# ATSAMRH71F20B device description
Architecture: CORTEX-M7; Family: SAMRH; Series: SAMRH71
Registers are 32-bit, read-write, no defined reset value unless marked. A register's access mark holds for its fields unless they carry their own. Offsets are from the block's base; [hi:lo] are bit positions; {n}, {i} and the like mark numbered series; 'fields as' and 'values as' point back to an identical list.

## HEMC
Instances: HEMC 0x40080000
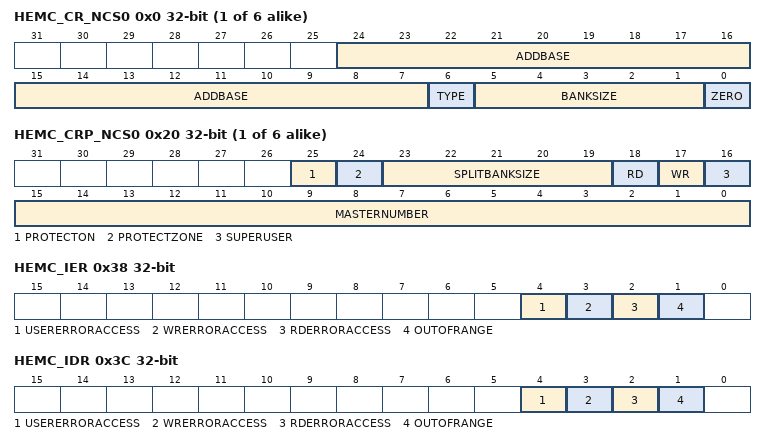
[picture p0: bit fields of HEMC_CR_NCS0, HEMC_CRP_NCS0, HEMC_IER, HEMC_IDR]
{0x0+4i} HEMC_CR_NCS{i} (i=0..5) — HEMC Control Register NCS {i}
  [24:7] ADDBASE — relative base address of NCS area
  [6] TYPE — type of memory used
  [5:1] BANKSIZE
    0=_8KB (8Kbytes); 1=_16KB (16Kbytes); 2=_32KB (32Kbytes); 3=_64KB (64Kbytes); 4=_128KB (128Kbytes); 5=_256KB (256Kbytes); 6=_512KB (512Kbytes); 7=_1MB (1Mbytes); 8=_2MB (2Mbytes); 9=_4MB (4Mbytes); 10=_8MB (8Mbytes); 11=_16MB (16Mbytes); 12=_32MB (32Mbytes); 13=_64MB (64Mbytes); 14=_128MB (128Mbytes); 15=_256MB (256Mbytes (Default)); 16=_512MB (512Mbytes); 31=NOT_USED
  [0] ZERO — fixed to 0
0x18 HEMC_CTRL — HEMC Polarity Control register
  [0] POL — External control buffer active polarity
{0x20+4i} HEMC_CRP_NCS{i} (i=0..5) — HEMC Control Register Protection NCS {i}
  [25] PROTECTON — protection activation
  [24] PROTECTZONE — select area protected
  [23:19] SPLITBANKSIZE — bank size internal separation
  [18] RD — Read Access
  [17] WR — Write Access
  [16] SUPERUSER — User or Superuser access
  [15:0] MASTERNUMBER — Master Number ID
0x38 HEMC_IER wo — HEMC Interrupt Enable Register
  [4] USERERRORACCESS — user or superuser access error
  [3] WRERRORACCESS — write access error
  [2] RDERRORACCESS — read access error
  [1] OUTOFRANGE
0x3C HEMC_IDR wo — HEMC Interrupt Disable Register
  fields as HEMC_IER
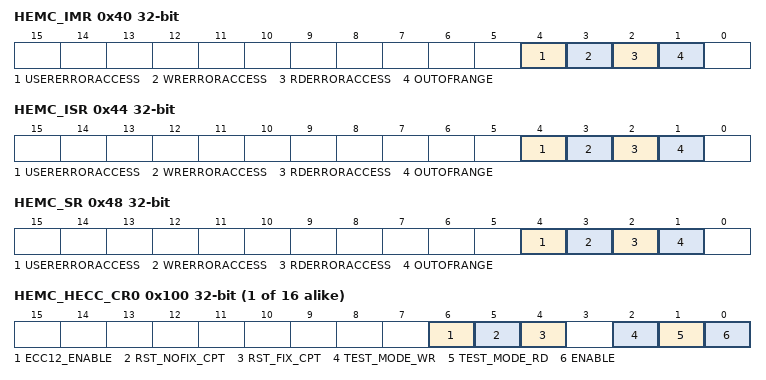
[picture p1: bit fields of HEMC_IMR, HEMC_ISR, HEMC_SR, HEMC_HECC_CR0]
0x40 HEMC_IMR ro — HEMC Interrupt Mask Register
  fields as HEMC_IER
0x44 HEMC_ISR ro — HEMC Interrupt Status Register
  [4] USERERRORACCESS — User or SuperUser Error Access
  [3] WRERRORACCESS — Write access error
  [2] RDERRORACCESS — read access error
  [1] OUTOFRANGE
0x48 HEMC_SR ro — HEMC Status Register
  [4] USERERRORACCESS — User or SuperUser Error Access
  [3] WRERRORACCESS — Write access error
  [2] RDERRORACCESS — Read access error
  [1] OUTOFRANGE
{0x100+4i} HEMC_HECC_CR{i} (i=0..15) — HECC Control Register (ChannelNumbers = 0) {i}
  [6] ECC12_ENABLE — BCH ECC enable
  [5] RST_NOFIX_CPT — reset the un-fixable error counter
  [4] RST_FIX_CPT — reset the fixable error counter
  [2] TEST_MODE_WR — test mode of ECC protection - write mode
  [1] TEST_MODE_RD — test mode of ECC protection - read mode
  [0] ENABLE — ECC protection enable
{0x140+4i} HEMC_HECC_TESTCB{i} (i=0..15) — HECC Test mode Register (ChannelNumbers = 0) {i}
  [15:0] TCB1 — test check bit (16 bit)
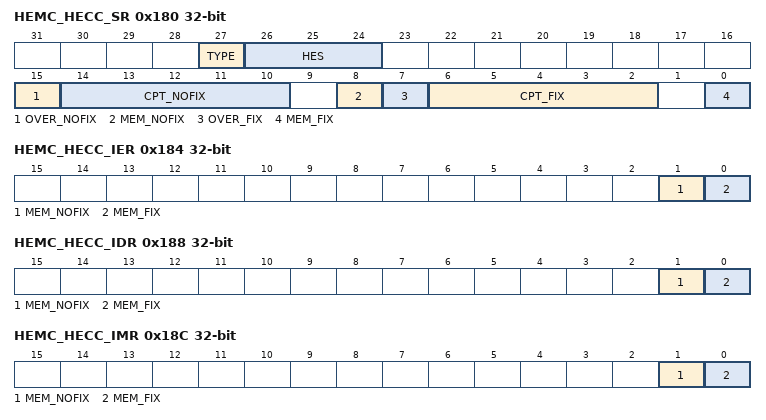
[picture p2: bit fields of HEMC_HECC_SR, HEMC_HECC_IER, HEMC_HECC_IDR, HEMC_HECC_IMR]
0x180 HEMC_HECC_SR ro — HECC Status Register
  [27] TYPE — write or read access
  [26:24] HES — Hardware Error Size
  [15] OVER_NOFIX — counter overflow
  [14:10] CPT_NOFIX — 5 bits counter
  [8] MEM_NOFIX — Un-fixable error status
  [7] OVER_FIX — counter overflow
  [6:2] CPT_FIX — 5 bits counter
  [0] MEM_FIX — Fixable error status
0x184 HEMC_HECC_IER wo — HECC Interrupt Enable Register
  [1] MEM_NOFIX — Un-fixable error
  [0] MEM_FIX — Fixable error
0x188 HEMC_HECC_IDR wo — HECC Interrupt Disable Register
  [1] MEM_NOFIX — un-fixable error
  [0] MEM_FIX — fixable error
0x18C HEMC_HECC_IMR ro — HECC Interrupt Mask Register
  [1] MEM_NOFIX — un-fixable error
  [0] MEM_FIX — fixable error
0x190 HEMC_HECC_FAILAR ro — HECC Fail address register
  [31:0] ADDRESS — address of the error detected

## HSMC — Harden Static Memory Controller
Instances: HSMC 0x40081000
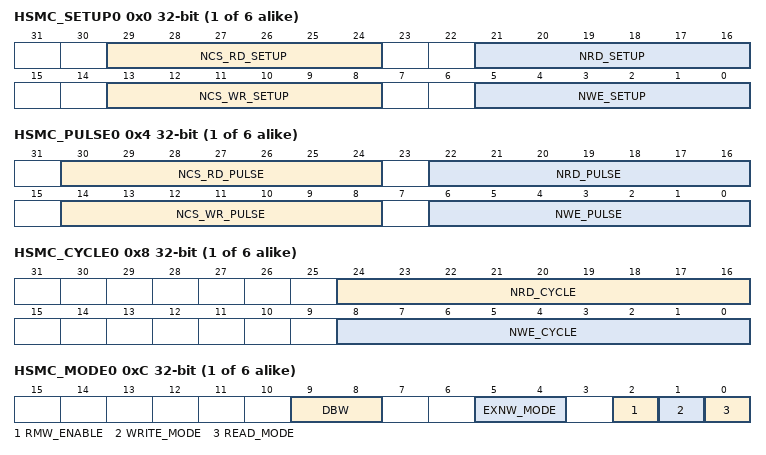
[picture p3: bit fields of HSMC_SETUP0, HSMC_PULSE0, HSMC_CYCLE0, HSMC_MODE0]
{0x0+0x10*i} HSMC_SETUP{i} (i=0..5) — HSMC Setup Register (CS_number = {i})
  [29:24] NCS_RD_SETUP — NCS Setup Length in READ Access
  [21:16] NRD_SETUP — NRD Setup Length
  [13:8] NCS_WR_SETUP — NCS Setup Length in WRITE Access
  [5:0] NWE_SETUP — NWE Setup Length
{0x4+0x10*i} HSMC_PULSE{i} (i=0..5) — HSMC Pulse Register (CS_number = {i})
  [30:24] NCS_RD_PULSE — NCS Pulse Length in READ Access
  [22:16] NRD_PULSE — NRD Pulse Length
  [14:8] NCS_WR_PULSE — NCS Pulse Length in WRITE Access
  [6:0] NWE_PULSE — NWE Pulse Length
{0x8+0x10*i} HSMC_CYCLE{i} (i=0..5) — HSMC Cycle Register (CS_number = {i})
  [24:16] NRD_CYCLE — Total Read Cycle Length
  [8:0] NWE_CYCLE — Total Write Cycle Length
{0xC+0x10*i} HSMC_MODE{i} (i=0..5) — HSMC Mode Register (CS_number = {i})
  [9:8] DBW — Data Bus Width
    0=_8_BIT (8-bit Data Bus); 1=_16_BIT (16-bit Data Bus); 2=_32_BIT (32-bit Data Bus)
  [5:4] EXNW_MODE — NWAIT Mode
    0=DISABLED (Disabled-The NWAIT input signal is ignored on the corresponding chip select.); 2=FROZEN (Frozen Mode-If asserted, the NWAIT signal freezes the current read or write cycle. After deassertion, the read/write cycle is resumed from the point where it was stopped.); 3=READY (Ready Mode-The NWAIT signal indicates the availability of the external device at the end of the pulse of the controlling read or write signal, to complete the access. If high, the access normally completes. If low, the access is extended until NWAIT returns high.)
  [2] RMW_ENABLE — Read-Modify Write enable
  [1] WRITE_MODE
  [0] READ_MODE
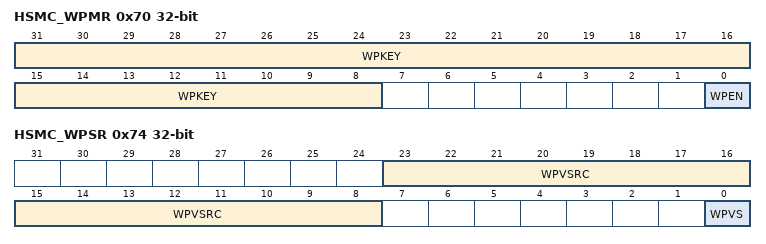
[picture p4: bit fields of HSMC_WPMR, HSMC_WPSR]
0x70 HSMC_WPMR — HSMC Write Protection Mode Register
  [31:8] WPKEY — Write Protection Key
    0x534D43=PASSWD (Writing any other value in this field aborts the write operation of the WPEN bit. Always reads as 0.)
  [0] WPEN — Write Protect Enable
0x74 HSMC_WPSR ro — HSMC Write Protection Status Register
  [23:8] WPVSRC — Write Protection Violation Source
  [0] WPVS — Write Protection Violation Status

## Notices in the file
Copyright (c) 2018 Microchip Technology Inc.
SPDX-License-Identifier: Apache-2.0
Licensed under the Apache License, Version 2.0 (the "License");
you may not use this file except in compliance with the License.
You may obtain a copy of the License at
http://www.apache.org/licenses/LICENSE-2.0
Unless required by applicable law or agreed to in writing, software
distributed under the License is distributed on an "AS IS" BASIS,
WITHOUT WARRANTIES OR CONDITIONS OF ANY KIND, either express or implied.
See the License for the specific language governing permissions and
limitations under the License.
